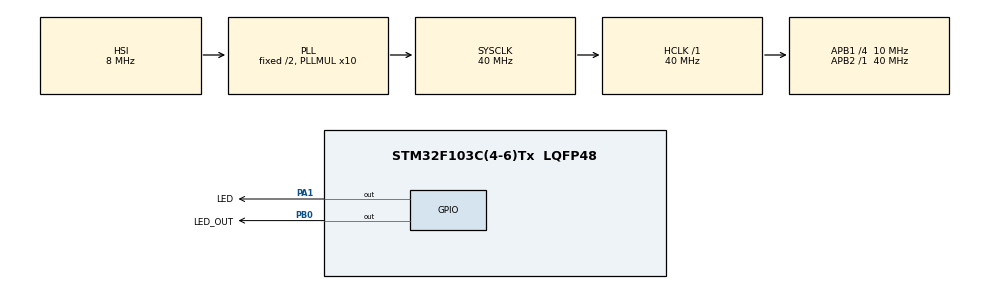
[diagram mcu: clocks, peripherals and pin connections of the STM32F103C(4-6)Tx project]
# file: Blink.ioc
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Mcu.Family=STM32F1
Mcu.Name=STM32F103C(4-6)Tx
Mcu.Package=LQFP48
NVIC.PriorityGroup=NVIC_PRIORITYGROUP_4
PA1.GPIO_Label=LED
PA1.Signal=GPIO_Output
PA13.Mode=Serial_Wire
PA13.Signal=SYS_JTMS-SWDIO
PA14.Mode=Serial_Wire
PA14.Signal=SYS_JTCK-SWCLK
PB0.GPIO_Label=LED_OUT
PB0.Signal=GPIO_Output
ProjectManager.HeapSize=0x200
ProjectManager.StackSize=0x400
ProjectManager.TargetToolchain=STM32CubeIDE
RCC.AHBFreq_Value=40000000
RCC.APB1CLKDivider=RCC_HCLK_DIV4
RCC.APB1Freq_Value=10000000
RCC.APB1TimFreq_Value=20000000
RCC.APB2Freq_Value=40000000
RCC.APB2TimFreq_Value=40000000
RCC.HCLKFreq_Value=40000000
RCC.PLLMUL=RCC_PLL_MUL10
RCC.SYSCLKFreq_VALUE=40000000
RCC.SYSCLKSource=RCC_SYSCLKSOURCE_PLLCLK
RCC.USBFreq_Value=40000000
board=custom

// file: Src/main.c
/* USER CODE BEGIN Header */
/**
  ******************************************************************************
  * @file           : main.c
  * @brief          : Main program body
  ******************************************************************************
  * @attention
  *
  * Copyright (c) 2023 STMicroelectronics.
  * All rights reserved.
  *
  * This software is licensed under terms that can be found in the LICENSE file
  * in the root directory of this software component.
  * If no LICENSE file comes with this software, it is provided AS-IS.
  *
  ******************************************************************************
  */
/* USER CODE END Header */
#include "main.h"

void SystemClock_Config(void);
static void MX_GPIO_Init(void);

int main(void)
{

  /* MCU Configuration--------------------------------------------------------*/

  /* Reset of all peripherals, Initializes the Flash interface and the Systick. */
  HAL_Init();

  /* Configure the system clock */
  SystemClock_Config();

  /* Initialize all configured peripherals */
  MX_GPIO_Init();

  /* Infinite loop */
  while (1)
  {

    /* USER CODE BEGIN 3 */
	  // HAL_GPIO_WritePin(LED_OUT_GPIO_Port, LED_OUT_Pin, GPIO_PIN_RESET);

	   HAL_GPIO_TogglePin(LED_GPIO_Port, LED_Pin);
	   // HAL_GPIO_TogglePin(LED_OUT_GPIO_Port, LED_OUT_Pin);
	   HAL_Delay(150);
	   HAL_GPIO_WritePin(LED_OUT_GPIO_Port, LED_OUT_Pin, GPIO_PIN_SET);
	   HAL_Delay(50);
	   HAL_GPIO_WritePin(LED_OUT_GPIO_Port, LED_OUT_Pin, GPIO_PIN_RESET);
	   HAL_Delay(250);
	   for (int i = 0; i < 10; i++) {
		   HAL_GPIO_TogglePin(LED_OUT_GPIO_Port, LED_OUT_Pin);
		   HAL_Delay(125);
	   }
	   HAL_Delay(250);
	   HAL_GPIO_WritePin(LED_OUT_GPIO_Port, LED_OUT_Pin, GPIO_PIN_SET);
	   HAL_Delay(50);
	   HAL_GPIO_WritePin(LED_OUT_GPIO_Port, LED_OUT_Pin, GPIO_PIN_RESET);
	   HAL_Delay(250);
  }
  /* USER CODE END 3 */
}

void SystemClock_Config(void)
{
  RCC_OscInitTypeDef RCC_OscInitStruct = {0};
  RCC_ClkInitTypeDef RCC_ClkInitStruct = {0};

  /** Initializes the RCC Oscillators according to the specified parameters
  * in the RCC_OscInitTypeDef structure.
  */
  RCC_OscInitStruct.OscillatorType = RCC_OSCILLATORTYPE_HSI;
  RCC_OscInitStruct.HSIState = RCC_HSI_ON;
  RCC_OscInitStruct.HSICalibrationValue = RCC_HSICALIBRATION_DEFAULT;
  RCC_OscInitStruct.PLL.PLLState = RCC_PLL_ON;
  RCC_OscInitStruct.PLL.PLLSource = RCC_PLLSOURCE_HSI_DIV2;
  RCC_OscInitStruct.PLL.PLLMUL = RCC_PLL_MUL10;
  if (HAL_RCC_OscConfig(&RCC_OscInitStruct) != HAL_OK)
  {
    Error_Handler();
  }

  /** Initializes the CPU, AHB and APB buses clocks
  */
  RCC_ClkInitStruct.ClockType = RCC_CLOCKTYPE_HCLK|RCC_CLOCKTYPE_SYSCLK
                              |RCC_CLOCKTYPE_PCLK1|RCC_CLOCKTYPE_PCLK2;
  RCC_ClkInitStruct.SYSCLKSource = RCC_SYSCLKSOURCE_PLLCLK;
  RCC_ClkInitStruct.AHBCLKDivider = RCC_SYSCLK_DIV1;
  RCC_ClkInitStruct.APB1CLKDivider = RCC_HCLK_DIV4;
  RCC_ClkInitStruct.APB2CLKDivider = RCC_HCLK_DIV1;

  if (HAL_RCC_ClockConfig(&RCC_ClkInitStruct, FLASH_LATENCY_1) != HAL_OK)
  {
    Error_Handler();
  }
}

static void MX_GPIO_Init(void)
{
  GPIO_InitTypeDef GPIO_InitStruct = {0};

  /* GPIO Ports Clock Enable */
  __HAL_RCC_GPIOA_CLK_ENABLE();
  __HAL_RCC_GPIOB_CLK_ENABLE();

  /*Configure GPIO pin Output Level */
  HAL_GPIO_WritePin(LED_GPIO_Port, LED_Pin, GPIO_PIN_RESET);

  /*Configure GPIO pin Output Level */
  HAL_GPIO_WritePin(LED_OUT_GPIO_Port, LED_OUT_Pin, GPIO_PIN_RESET);

  /*Configure GPIO pin : LED_Pin */
  GPIO_InitStruct.Pin = LED_Pin;
  GPIO_InitStruct.Mode = GPIO_MODE_OUTPUT_PP;
  GPIO_InitStruct.Pull = GPIO_NOPULL;
  GPIO_InitStruct.Speed = GPIO_SPEED_FREQ_LOW;
  HAL_GPIO_Init(LED_GPIO_Port, &GPIO_InitStruct);

  /*Configure GPIO pin : LED_OUT_Pin */
  GPIO_InitStruct.Pin = LED_OUT_Pin;
  GPIO_InitStruct.Mode = GPIO_MODE_OUTPUT_PP;
  GPIO_InitStruct.Pull = GPIO_NOPULL;
  GPIO_InitStruct.Speed = GPIO_SPEED_FREQ_LOW;
  HAL_GPIO_Init(LED_OUT_GPIO_Port, &GPIO_InitStruct);

}

void Error_Handler(void)
{
  __disable_irq();
  while (1)
  {
  }
}
